# STM32U375xx register map
File version: 1.0
Registers are 32-bit, read-write, reset 0x0 unless marked. A register's access mark holds for its fields unless they carry their own. Offsets are from the block's base; [hi:lo] are bit positions; {n}, {i} and the like mark numbered series; 'fields as' and 'values as' point back to an identical list.

## FDCAN_CONFIG — FD Controller Area Network Configuration
Base 0x4000A500
0x00 CKDIV — FDCAN clock divider register
  [3:0] PDIV — Input Clock Divider
0x204 OPTR — FDCAN option register
0x2F0 HWCFG — FDCAN hardware configuration register
0x2F4 VERR — FDCAN IP version register
0x2F8 IPIDR — FDCAN IP ID register
0x2FC SIDR — FDCAN size ID register

## SAI1 — Serial Audio Interface
Base 0x40015400
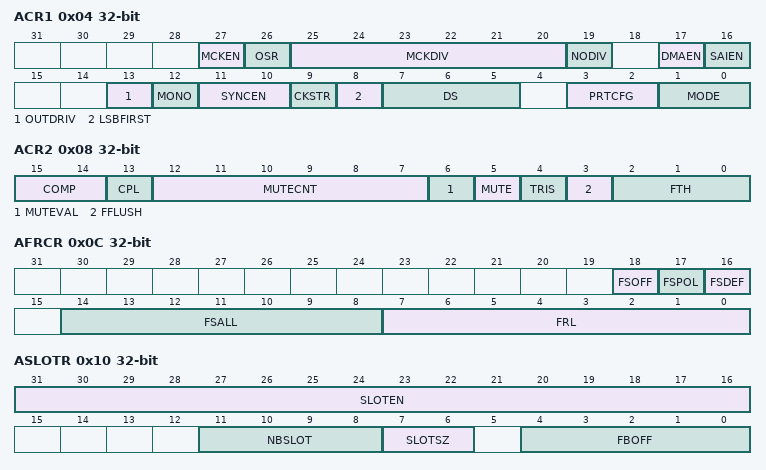
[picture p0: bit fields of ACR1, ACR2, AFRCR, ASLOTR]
0x04 ACR1 — SAI block x configuration register 1
  [27] MCKEN — Master clock generation enable
  [26] OSR — Oversampling ratio for master clock
  [25:20] MCKDIV — MCKDIV[5:0] (Master ClocK Divider)
  [19] NODIV — No Divider Configuration
  [17] DMAEN — DMA enable
  [16] SAIEN — Audio Block enable
  [13] OUTDRIV — Output Drive
  [12] MONO — Mono mode
  [11:10] SYNCEN — SYNCEN[1:0](SYNChronization ENable)
  [9] CKSTR — ClocK STRobing edge
  [8] LSBFIRST — LSB First Configuration
  [7:5] DS — DS[1:0] bits (Data Size)
  [3:2] PRTCFG — PRTCFG[1:0] bits (Protocol Configuration)
  [1:0] MODE — MODE[1:0] bits (Audio Block Mode)
0x08 ACR2 — SAI block x configuration register 2
  [15:14] COMP — COMP[1:0] (Companding mode)
  [13] CPL — CPL mode
  [12:7] MUTECNT — MUTECNT[5:0] (MUTE counter)
  [6] MUTEVAL — Muate value
  [5] MUTE — Mute mode
  [4] TRIS — TRIState Management on data line
  [3] FFLUSH — Fifo FLUSH
  [2:0] FTH — FTH[2:0](Fifo THreshold)
0x0C AFRCR — SAI block x frame configuration register
  [18] FSOFF — Frame Synchronization OFFset
  [17] FSPOL — Frame Synchronization POLarity
  [16] FSDEF — Frame Synchronization Definition
  [14:8] FSALL — FRL[6:0] (Frame synchronization active level length)
  [7:0] FRL — FRL[7:0](Frame length)
0x10 ASLOTR — SAI block x slot register
  [31:16] SLOTEN — SLOTEN[15:0] (Slot Enable)
  [11:8] NBSLOT — NBSLOT[3:0] (Number of Slot in audio Frame)
  [7:6] SLOTSZ — SLOTSZ[1:0] (Slot size)
  [4:0] FBOFF — FRL[4:0](First Bit Offset)
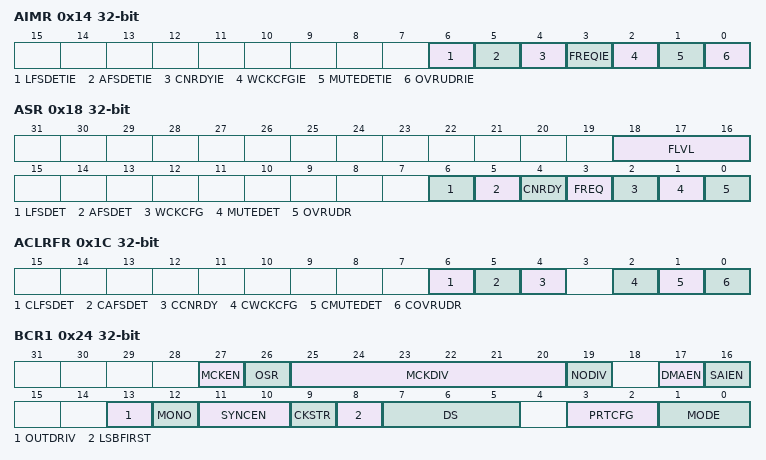
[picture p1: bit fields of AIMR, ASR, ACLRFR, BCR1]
0x14 AIMR — SAI block x interrupt mask register
  [6] LFSDETIE — Late frame synchronization detection interrupt enable
  [5] AFSDETIE — Anticipated frame synchronization detection interrupt enable
  [4] CNRDYIE — Codec not ready interrupt enable
  [3] FREQIE — FIFO request interrupt enable
  [2] WCKCFGIE — Wrong Clock Configuration interrupt enable
  [1] MUTEDETIE — Mute detection interrupt enable
  [0] OVRUDRIE — Overrun underrun interrupt enable
0x18 ASR — SAI block x status register
  [18:16] FLVL — FLVL[2:0] (FIFO Level Threshold)
  [6] LFSDET — Late frame synchronization detection
  [5] AFSDET — Anticipated frame synchronization detection
  [4] CNRDY — Codec not ready
  [3] FREQ — FIFO request
  [2] WCKCFG — Wrong Clock Configuration
  [1] MUTEDET — Mute detection
  [0] OVRUDR — Overrun underrun
0x1C ACLRFR — SAI block x clear flag register
  [6] CLFSDET — Clear Late frame synchronization detection
  [5] CAFSDET — Clear Anticipated frame synchronization detection
  [4] CCNRDY — Clear Codec not ready
  [2] CWCKCFG — Clear Wrong Clock Configuration
  [1] CMUTEDET — Clear Mute detection
  [0] COVRUDR — Clear Overrun underrun
0x20 ADR — SAI block x data register
  [31:0] DATA
0x24 BCR1 — SAI block x configuration register 1
  fields as ACR1
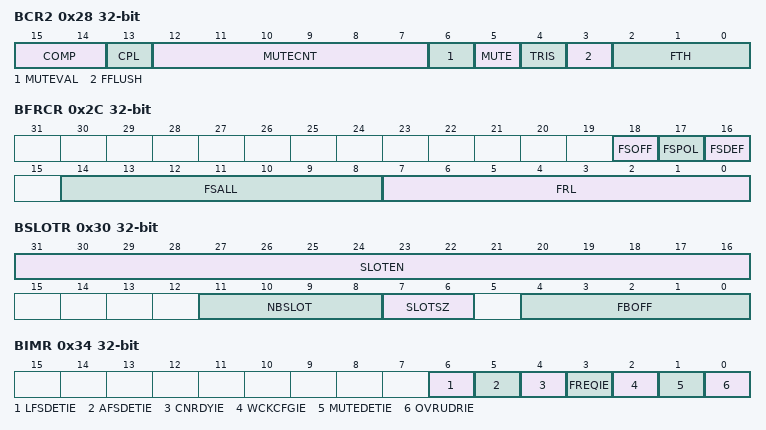
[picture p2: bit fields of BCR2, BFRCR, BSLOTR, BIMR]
0x28 BCR2 — SAI block x configuration register 2
  fields as ACR2
0x2C BFRCR — SAI block x frame configuration register
  fields as AFRCR
0x30 BSLOTR — SAI block x slot register
  fields as ASLOTR
0x34 BIMR — SAI block x interrupt mask register
  fields as AIMR
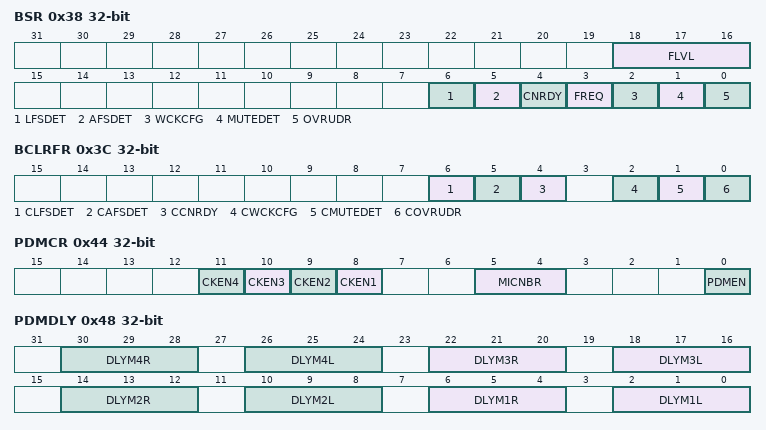
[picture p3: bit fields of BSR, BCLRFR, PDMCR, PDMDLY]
0x38 BSR — SAI block x status register
  fields as ASR
0x3C BCLRFR — SAI block x clear flag register
  fields as ACLRFR
0x40 BDR — SAI block x data register
  [31:0] DATA
0x44 PDMCR — SAI PDM control register
  [n+7] CKEN{n} (n=1..4) — Clock {n} enable
  [5:4] MICNBR — MICNBR[1:0] (Number of microphones)
  [0] PDMEN — PDM enable
0x48 PDMDLY — SAI PDM delay register
  [8n-2:8n-4] DLYM{n}R (n=1..4) — DLYM{n}R[2:0] (Delay line adjust for right microphone of pair {n})
  [8n-6:8n-8] DLYM{n}L (n=1..4) — DLYM{n}L[2:0] (Delay line adjust for left microphone of pair {n})
